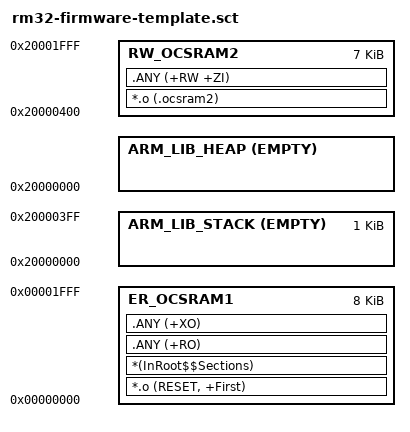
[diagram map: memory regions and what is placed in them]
#! armclang -E --target=arm-arm-none-eabi -mcpu=cortex-m0 -xc

#define __OCSRAM1_BASE         (0x00000000)
#define __OCSRAM1_SIZE         (0x00002000)
#define __OCSRAM2_BASE         (0x20000000)
#define __OCSRAM2_SIZE         (0x00002000)

#define __HEAP_BASE            (__OCSRAM2_BASE)
#define __HEAP_SIZE            (0x00000000)

#define __STACK_BASE           (__OCSRAM2_BASE + __HEAP_SIZE)
#define __STACK_SIZE           (0x00000400)

#define __USER_OCSRAM2_BASE    (__OCSRAM2_BASE + __HEAP_SIZE + __STACK_SIZE)
#define __USER_OCSRAM2_SIZE    (__OCSRAM2_SIZE - __HEAP_SIZE - __STACK_SIZE)

OCSRAM1 __OCSRAM1_BASE __OCSRAM1_SIZE {
    ER_OCSRAM1 __OCSRAM1_BASE __OCSRAM1_SIZE {
        *.o (RESET, +First)
        *(InRoot$$Sections)
        .ANY (+RO)
        .ANY (+XO)
    }

    ARM_LIB_STACK __STACK_BASE ALIGN 8 EMPTY __STACK_SIZE {
    }

    ARM_LIB_HEAP __HEAP_BASE ALIGN 8 EMPTY __HEAP_SIZE {
    }

    RW_OCSRAM2 __USER_OCSRAM2_BASE __USER_OCSRAM2_SIZE {
        *.o (.ocsram2)
        .ANY (+RW +ZI)
    }
}
